# ipro7 register map
Vendor: intelpro; Series: BTBLE
CPU: ipro7, little endian
Registers are 32-bit, read-write, reset 0x0 unless marked. A register's access mark holds for its fields unless they carry their own. Offsets are from the block's base; [hi:lo] are bit positions; {n}, {i} and the like mark numbered series.

## EMAC
Base 0x30083000
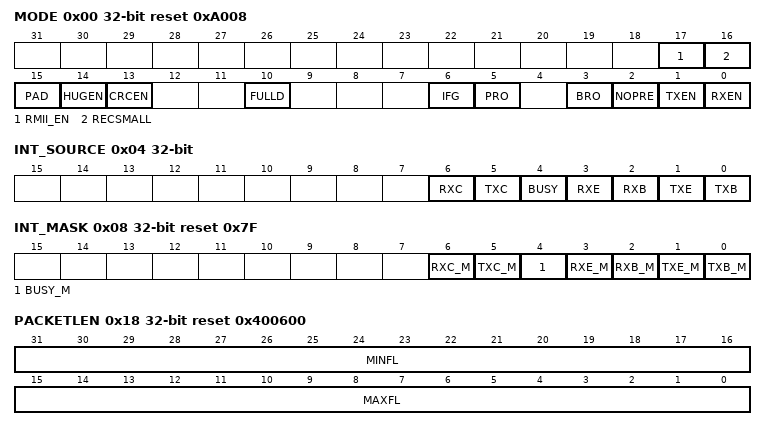
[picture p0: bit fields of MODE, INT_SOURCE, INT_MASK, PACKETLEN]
0x00 MODE reset 0xA008
  [17] RMII_EN — RMII mode enable 0: MII PHY I/F is used 1: RMII PHY I/F is used
  [16] RECSMALL — Receive small frame enable 0: Frames smaller than MINFL are ignored. 1: Frames smaller than MINFL are accepted.
  [15] PAD — Padding enable 0: Do not add pads to frames shorter than MINFL. 1: Add pads to short frames, until the length equals MINFL.
  [14] HUGEN — Huge frames enable 0: The maximum frame length is MAXFL. All additional bytes are dropped. 1: Frame size is not limited by MAXFL and can be up to 64K bytes.
  [13] CRCEN — CRC Enable 0: TX MAC does not append CRC field. 1: TX MAC will append CRC field to every frame.
  [10] FULLD — Full duplex 0: Half duplex mode. 1: Full duplex mode.
  [6] IFG — Inter frame gap check 0: IFG is verified before each frame be received. 1: All frames are received regardless to IFG requirement.
  [5] PRO — Promiscuous mode enable 0: The destination address is checked before receiving. 1: All frames received regardless of the address.
  [3] BRO — Broadcast address enable 0: Reject all frames containing the broadcast address unless the PRO bit is asserted. 1: Receive all frames containing broadcast address.
  [2] NOPRE — No preamble mode 0: 7-byte preamble will be sent. 1: No preamble will be sent.
  [1] TXEN — Transmit enable 0: Transmitter is disabled. 1: Transmitter is enabled. If TX_BD_NUM equals 0x0 (zero buffer descriptors are used), then the transmitter is disabled regardless of TXEN.
  [0] RXEN — Receiver enable 0: Receiver is disabled. 1: Receiver is enabled. If TX_BD_NUM equals 0x80 (all buffer descriptors are used for TX), then the receiver is disabled regardless of RXEN.
0x04 INT_SOURCE
  [6] RXC — Receive control frame This bit indicates that the control frame was received. It is cleared by writing 1 to it. Bit RXFLOW in the CTRLMODE register must be set to 1 in order to get the RXC bit set.
  [5] TXC — Transmit control frame This bit indicates that a control frame was transmitted. It is cleared by writing 1 to it. Bit TXFLOW in the CTRLMODE register must be set to 1 in order to get the TXC bit set.
  [4] BUSY — Busy This bit indicates that RX packet is being received and there is no empty buffer descriptor to use. It iscleared by writing 1 to it. This bit appears regardless to the IRQ bits in the Receive Buffer Descriptor.
  [3] RXE — Receive error This bit indicates that an error occurred while receiving data (overrun, receiver error, dribble nibble, too long, >64K, CRC error, bus error or late collision. It is cleared by writing 1 to it. This bit appears only when IRQ bit is set in the Receive Buffer Descriptor.
  [2] RXB — Receive frame This bit indicates that a frame was received. It is cleared by writing 1 to it. This bit appears only when IRQ bit is set in the Receive Buffer Descriptor.
  [1] TXE — Transmit error This bit indicates that a buffer was not transmitted due to a transmit error (underrun, retransmission limit, late collision, bus error or defer timeout). It is cleared by writing 1 to it. This bit appears only when IRQ bit is set in the Transmit Buffer Descriptor.
  [0] TXB — Transmit buffer This bit indicates that a buffer has been transmitted. It is cleared by writing 1 to it. This bit appears only when IRQ bit is set in the Transmit Buffer Descriptor.
0x08 INT_MASK reset 0x7F
  [6] RXC_M — Receive control frame mask ENABLE 0: Interrupt is un-masked 1: Interrupt is masked
  [5] TXC_M — Transmit control frame mask ENABLE 0: Interrupt is un-masked 1: Interrupt is masked
  [4] BUSY_M — Busy mask ENABLE 0: Interrupt is un-masked 1: Interrupt is masked
  [3] RXE_M — Receive error mask ENABLE 0: Interrupt is un-masked 1: Interrupt is masked
  [2] RXB_M — Receive frame mask ENABLE 0: Interrupt is un-masked 1: Interrupt is masked
  [1] TXE_M — Transmit error mask ENABLE 0: Interrupt is un-masked 1: Interrupt is masked
  [0] TXB_M — Transmit buffer mask ENABLE 0: Interrupt is un-masked 1: Interrupt is masked
0x0C IPGT reset 0x18
  [6:0] IPGT — Inter packet gap The recommended value is 0x18 (24 clock cycles), which equals 9.6 us for 10 Mbps and 0.96 us for 100 Mbps mode
0x18 PACKETLEN reset 0x400600
  [31:16] MINFL — Minimum frame length The minimum Ethernet packet is 64 bytes long (0x40). To receive small packets, assert the RECSMALL bit or change the MINFL value. To transmit small packets, assert the PAD bit or change the MINFL value.
  [15:0] MAXFL — Maximum frame length The maximum Ethernet packet is 1518 bytes long. To support this and to have some additional space for tags, a default maximum packet length equals to 1536 bytes (0x600). For bigger packets, you can assert the HUGEN bit or increase the value of MAXFL field.
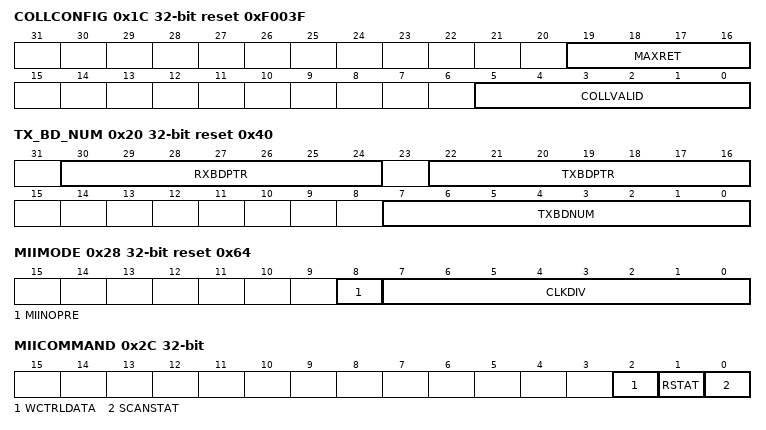
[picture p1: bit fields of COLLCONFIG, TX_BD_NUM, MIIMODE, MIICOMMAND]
0x1C COLLCONFIG reset 0xF003F
  [19:16] MAXRET — Maximum retry This field specifies the maximum number of consequential retransmission attempts after the collision is detected. When the maximum number has been reached, the TX MAC reports an error and stops transmitting the current packet. According to the Ethernet standard, the MAXRET default value is set to 0xf (15).
  [5:0] COLLVALID — Collision valid This field specifies a collision time window. A collision that occurs later than the time window is reported as a "Late Collisions" and transmission of the current packet is aborted.
0x20 TX_BD_NUM reset 0x40 (reset mask 0x8080FFFF)
  [30:24] RXBDPTR ro — RX buffer descriptors (BD) pointer, pointing at the RXBD currently being used
  [22:16] TXBDPTR ro — TX buffer descriptors (BD) pointer, pointing at the TXBD currently being used
  [7:0] TXBDNUM — TX buffer descriptors (BD) number Number of TX BD. TX and RX share 128 (0x80) descriptors, so the number of RX BD equals 0x80 - TXBDNUM. The maximum number of TXBDNUM is 0x80. Values greater then 0x80 cannot be written into this register.
0x28 MIIMODE reset 0x64
  [8] MIINOPRE — No preamble for Management Data (MD) 0: 32-bit preamble will be sent. 1: No preamble will be sent.
  [7:0] CLKDIV — Clock divider for Management Data Clock (MDC) The source clock is bus clock and can be divided by any even number.
0x2C MIICOMMAND
  [2] WCTRLDATA — Write control data, setting this bit to 1 will trigger the command (auto cleared) Note: [2]/[1]/[0] cannot be asserted at the same time, execute one command at a time
  [1] RSTAT — Read status, setting this bit to 1 will trigger the command (auto cleared) Note: [2]/[1]/[0] cannot be asserted at the same time, execute one command at a time
  [0] SCANSTAT — Scan status, setting this bit to 1 will trigger the command (auto cleared) Note: [2]/[1]/[0] cannot be asserted at the same time, execute one command at a time
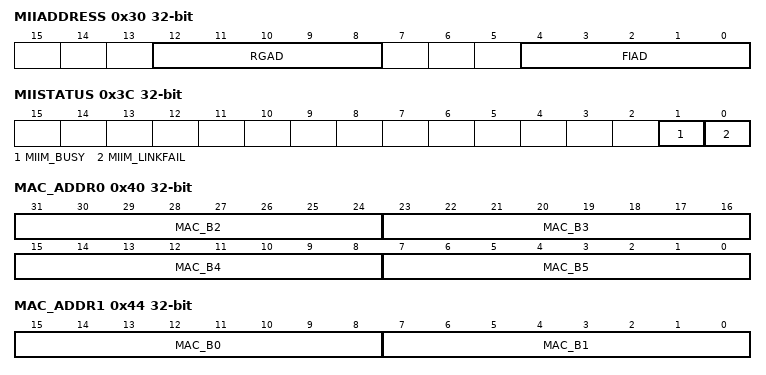
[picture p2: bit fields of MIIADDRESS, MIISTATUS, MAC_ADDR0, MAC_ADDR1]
0x30 MIIADDRESS
  [12:8] RGAD — Register Address
  [4:0] FIAD — PHY Address
0x34 MIITX_DATA
  [15:0] CTRLDATA — Control Data to be written to PHY
0x38 MIIRX_DATA (reset mask 0xFFFF0000)
  [15:0] PRSD ro — Received Data from PHY
0x3C MIISTATUS (reset mask 0xFFFFFFFC)
  [1] MIIM_BUSY ro — MIIM I/F busy signal 0: The MIIM I/F is ready. 1: The MIIM I/F is busy.
  [0] MIIM_LINKFAIL ro — MIIM I/F link fail signal
0x40 MAC_ADDR0
  [47-8n:40-8n] MAC_B{n} (n=2..5) — Ethernet MAC address byte {n}
0x44 MAC_ADDR1
  [15:8] MAC_B0 — Ethernet MAC address byte 0
  [7:0] MAC_B1 — Ethernet MAC address byte 1
0x48 HASH0_ADDR
  [31:0] HASH0 — Lower 32-bit of HASH register
0x4C HASH1_ADDR
  [31:0] HASH1 — Upper 32-bit of HASH register
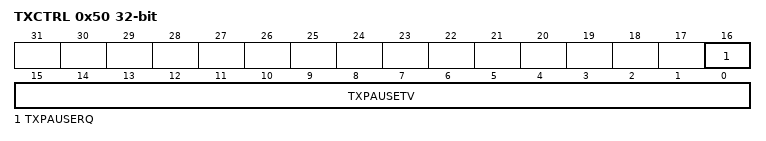
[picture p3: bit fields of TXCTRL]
0x50 TXCTRL
  [16] TXPAUSERQ — TX Pause Request Writing 1 to this bit starts sending control frame and is automatically cleared to zero.
  [15:0] TXPAUSETV — TX Pause Timer Value The value that is sent in the pause control frame.
